# ADSP-2183x_LPC register map
Vendor: Analog Devices; Series: ADSP-2183x_LPC; File version: 3.0.3.517
CPU: 
Registers are 32-bit, read-write, reset 0x0 unless marked. A register's access mark holds for its fields unless they carry their own. Offsets are from the block's base; [hi:lo] are bit positions; {n}, {i} and the like mark numbered series; 'fields as' and 'values as' point back to an identical list.

## DAPROM0
Base 0x31100000
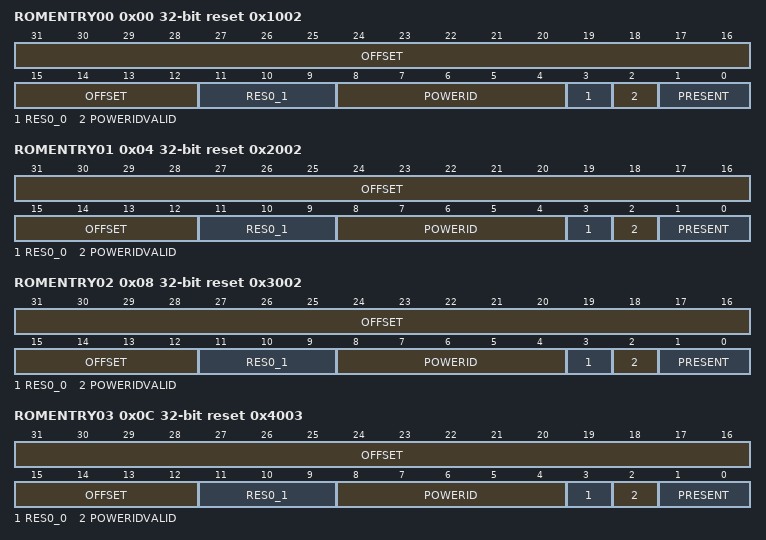
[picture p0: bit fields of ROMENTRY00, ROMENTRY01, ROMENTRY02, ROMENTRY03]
0x00 ROMENTRY00 reset 0x1002 — ROM Entries Register 0.
  [31:12] OFFSET ro, [11:9] RES0_1 ro, [8:4] POWERID ro, [3] RES0_0 ro, [2] POWERIDVALID ro, [1:0] PRESENT ro
0x04 ROMENTRY01 reset 0x2002 — ROM Entries Register 1.
  fields as ROMENTRY00
0x08 ROMENTRY02 reset 0x3002 — ROM Entries Register 2.
  fields as ROMENTRY00
0x0C ROMENTRY03 reset 0x4003 — ROM Entries Register 3.
  fields as ROMENTRY00
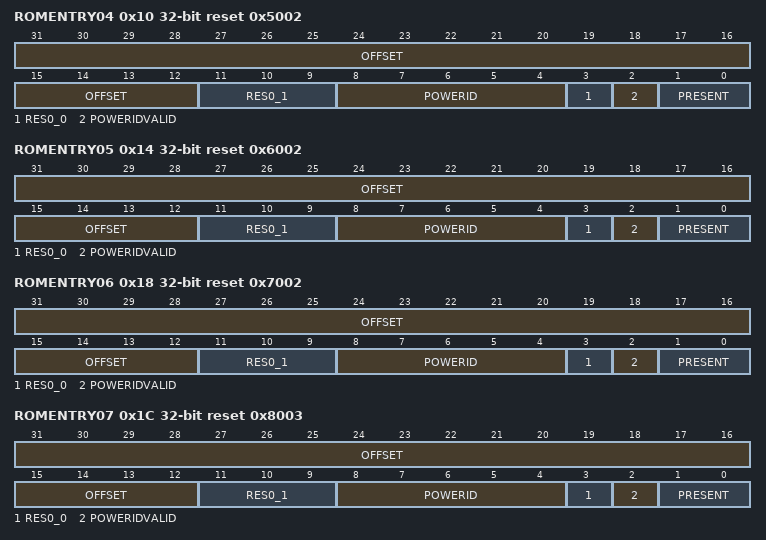
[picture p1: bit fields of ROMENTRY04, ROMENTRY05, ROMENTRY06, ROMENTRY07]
0x10 ROMENTRY04 reset 0x5002 — ROM Entries Register 4.
  fields as ROMENTRY00
0x14 ROMENTRY05 reset 0x6002 — ROM Entries Register 5.
  fields as ROMENTRY00
0x18 ROMENTRY06 reset 0x7002 — ROM Entries Register 6.
  fields as ROMENTRY00
0x1C ROMENTRY07 reset 0x8003 — ROM Entries Register 7.
  fields as ROMENTRY00
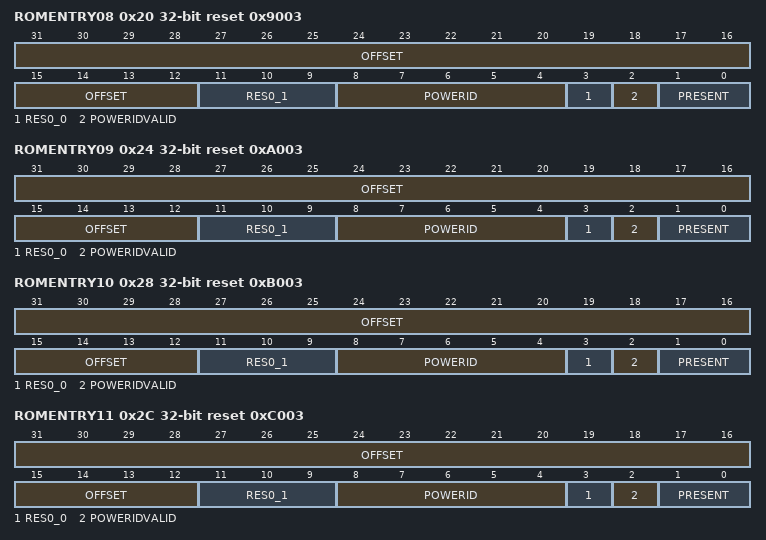
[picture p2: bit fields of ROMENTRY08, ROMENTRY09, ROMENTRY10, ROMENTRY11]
0x20 ROMENTRY08 reset 0x9003 — ROM Entries Register 8.
  fields as ROMENTRY00
0x24 ROMENTRY09 reset 0xA003 — ROM Entries Register 9.
  fields as ROMENTRY00
0x28 ROMENTRY10 reset 0xB003 — ROM Entries Register 10.
  fields as ROMENTRY00
0x2C ROMENTRY11 reset 0xC003 — ROM Entries Register 11.
  fields as ROMENTRY00
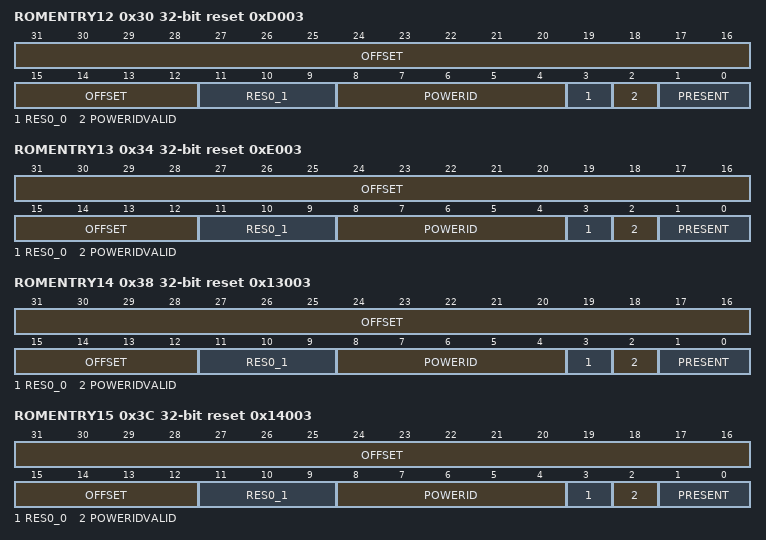
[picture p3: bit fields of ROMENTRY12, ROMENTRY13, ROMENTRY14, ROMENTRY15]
0x30 ROMENTRY12 reset 0xD003 — ROM Entries Register 12.
  fields as ROMENTRY00
0x34 ROMENTRY13 reset 0xE003 — ROM Entries Register 13.
  fields as ROMENTRY00
0x38 ROMENTRY14 reset 0x13003 — ROM Entries Register 14.
  fields as ROMENTRY00
0x3C ROMENTRY15 reset 0x14003 — ROM Entries Register 15.
  fields as ROMENTRY00
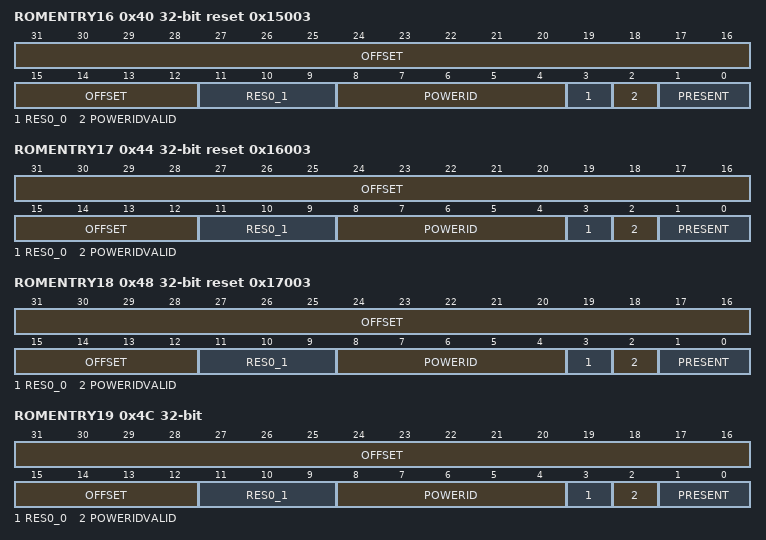
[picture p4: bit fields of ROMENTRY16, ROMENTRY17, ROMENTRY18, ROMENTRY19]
0x40 ROMENTRY16 reset 0x15003 — ROM Entries Register 16.
  fields as ROMENTRY00
0x44 ROMENTRY17 reset 0x16003 — ROM Entries Register 17.
  fields as ROMENTRY00
0x48 ROMENTRY18 reset 0x17003 — ROM Entries Register 18.
  fields as ROMENTRY00
0x4C ROMENTRY19 — ROM Entries Register 19.
  fields as ROMENTRY00
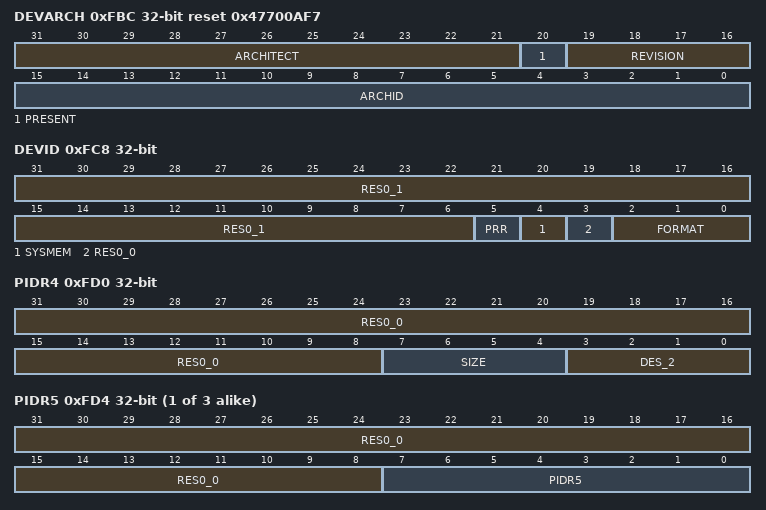
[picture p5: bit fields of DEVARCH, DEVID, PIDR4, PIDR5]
0xFBC DEVARCH reset 0x47700AF7 — Device Architecture Register.
  [31:21] ARCHITECT ro, [20] PRESENT ro, [19:16] REVISION ro, [15:0] ARCHID ro
0xFC8 DEVID — Device Configuration Register.
  [31:6] RES0_1 ro, [5] PRR ro, [4] SYSMEM ro, [3] RES0_0 ro, [2:0] FORMAT ro
0xFD0 PIDR4 — Peripheral Identification Register 4.
  [31:8] RES0_0 ro, [7:4] SIZE ro, [3:0] DES_2 ro
{0xFC0+4i} PIDR{i} (i=5..7) — Peripheral Identification Register {i}.
  [31:8] RES0_0 ro, [7:0] PIDR{i} ro
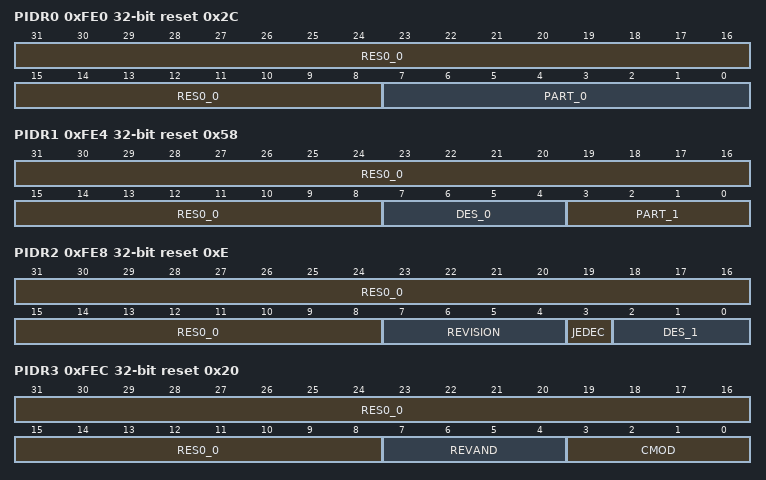
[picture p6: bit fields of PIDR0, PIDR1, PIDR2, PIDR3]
0xFE0 PIDR0 reset 0x2C — Peripheral Identification Register 0.
  [31:8] RES0_0 ro, [7:0] PART_0 ro
0xFE4 PIDR1 reset 0x58 — Peripheral Identification Register 1.
  [31:8] RES0_0 ro, [7:4] DES_0 ro, [3:0] PART_1 ro
0xFE8 PIDR2 reset 0xE — Peripheral Identification Register 2.
  [31:8] RES0_0 ro, [7:4] REVISION ro, [3] JEDEC ro, [2:0] DES_1 ro
0xFEC PIDR3 reset 0x20 — Peripheral Identification Register 3.
  [31:8] RES0_0 ro, [7:4] REVAND ro, [3:0] CMOD ro
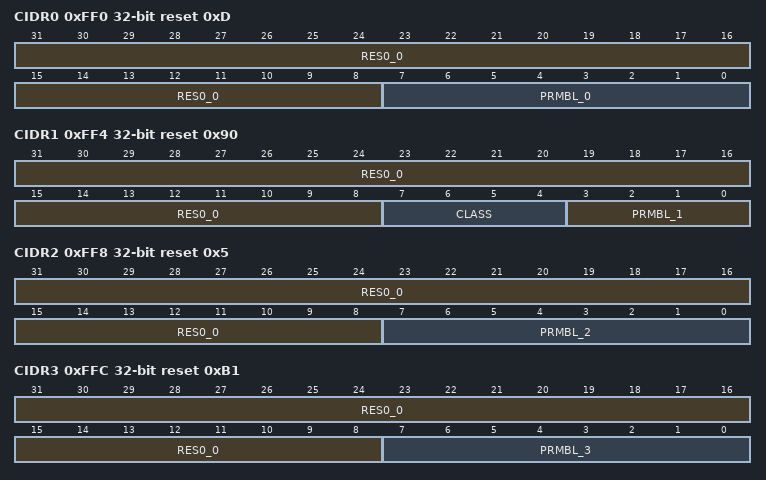
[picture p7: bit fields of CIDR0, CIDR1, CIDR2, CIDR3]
0xFF0 CIDR0 reset 0xD — Component Identification Register 0.
  [31:8] RES0_0 ro, [7:0] PRMBL_0 ro
0xFF4 CIDR1 reset 0x90 — Component Identification Register 1.
  [31:8] RES0_0 ro, [7:4] CLASS ro, [3:0] PRMBL_1 ro
0xFF8 CIDR2 reset 0x5 — Component Identification Register 2.
  [31:8] RES0_0 ro, [7:0] PRMBL_2 ro
0xFFC CIDR3 reset 0xB1 — Component Identification Register 3.
  [31:8] RES0_0 ro, [7:0] PRMBL_3 ro

## Trax_Registers
Base 0x31114000
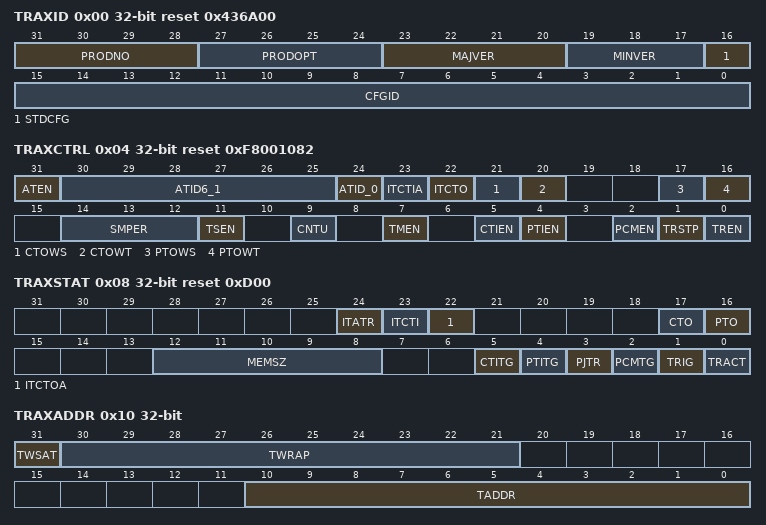
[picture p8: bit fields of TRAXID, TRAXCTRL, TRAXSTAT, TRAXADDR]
0x00 TRAXID reset 0x436A00
  [31:28] PRODNO ro, [27:24] PRODOPT ro, [23:20] MAJVER ro, [19:17] MINVER ro, [16] STDCFG ro, [15:0] CFGID ro
0x04 TRAXCTRL reset 0xF8001082
  [31] ATEN range 0x00000000..0x00000001
  [30:25] ATID6_1 range 0x00000000..0x0000003F
  [24] ATID_0 range 0x00000000..0x00000001
  [23] ITCTIA range 0x00000000..0x00000001
  [22] ITCTO range 0x00000000..0x00000001
  [21] CTOWS range 0x00000000..0x00000001
  [20] CTOWT range 0x00000000..0x00000001
  [17] PTOWS range 0x00000000..0x00000001
  [16] PTOWT range 0x00000000..0x00000001
  [14:12] SMPER
    0=SMNone; 1=SMPER256; 2=SMPER128; 3=SMPER64; 4=SMPER32; 5=SMPER16; 6=SMPER8
  [11] TSEN range 0x00000000..0x00000001
  [9] CNTU range 0x00000000..0x00000001
  [7] TMEN range 0x00000000..0x00000001
  [5] CTIEN range 0x00000000..0x00000001
  [4] PTIEN range 0x00000000..0x00000001
  [2] PCMEN range 0x00000000..0x00000001
  [1] TRSTP range 0x00000000..0x00000001
  [0] TREN range 0x00000000..0x00000001
0x08 TRAXSTAT reset 0xD00
  [24] ITATR ro, [23] ITCTI ro, [22] ITCTOA ro, [17] CTO ro, [16] PTO ro, [12:8] MEMSZ ro, [5] CTITG ro, [4] PTITG ro, [3] PJTR ro, [2] PCMTG ro, [1] TRIG ro, [0] TRACT ro
0x0C TRAXDATA
  [31:0] TRAXDATA range 0x00000000..0xFFFFFFFF
0x10 TRAXADDR
  [31] TWSAT range 0x00000000..0x00000001, [30:21] TWRAP range 0x00000000..0x000003FF, [10:0] TADDR range 0x00000000..0x000007FF
0x14 TRIGGERPC
  [31:0] TRIGGERPC range 0x00000000..0xFFFFFFFF
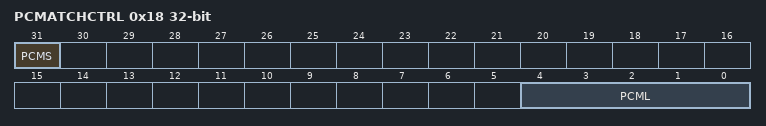
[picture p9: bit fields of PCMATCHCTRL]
0x18 PCMATCHCTRL
  [31] PCMS range 0x00000000..0x00000001, [4:0] PCML range 0x00000000..0x0000001F
0x1C DELAYCNT
  [23:0] DELAYCNT range 0x00000000..0x00FFFFFF
0x20 MEMADDRSTART
  [10:0] MEMADDRSTART range 0x00000000..0x000007FF
0x24 MEMADDREND reset 0x7FF
  [10:0] MEMADDREND range 0x00000000..0x000007FF
0x40 EXTTIMELO
  [31:0] EXTTIMELO ro
0x44 EXTTIMEHI
  [31:0] EXTTIMEHI ro
